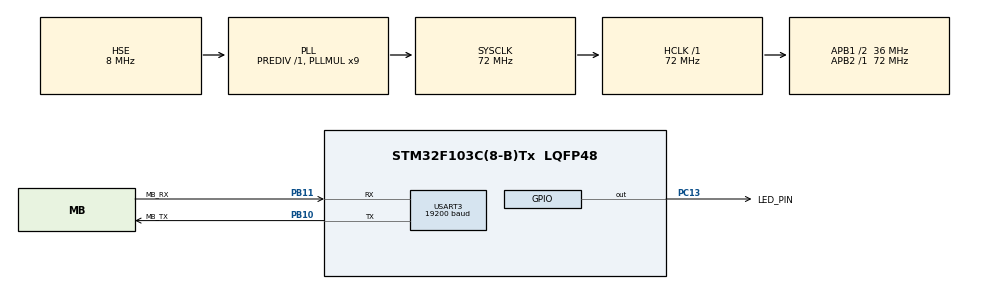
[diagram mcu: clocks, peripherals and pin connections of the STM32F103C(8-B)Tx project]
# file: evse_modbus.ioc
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Mcu.Family=STM32F1
Mcu.Name=STM32F103C(8-B)Tx
Mcu.Package=LQFP48
NVIC.PriorityGroup=NVIC_PRIORITYGROUP_4
NVIC.USART3_IRQn=true\:0\:0\:false\:false\:true\:true\:true\:true
PA13.Mode=Serial_Wire
PA13.Signal=SYS_JTMS-SWDIO
PA14.Mode=Serial_Wire
PA14.Signal=SYS_JTCK-SWCLK
PB10.GPIO_Label=MB_TX
PB10.Mode=Asynchronous
PB10.Signal=USART3_TX
PB11.GPIO_Label=MB_RX
PB11.Mode=Asynchronous
PB11.Signal=USART3_RX
PC13-TAMPER-RTC.GPIO_Label=LED_PIN
PC13-TAMPER-RTC.Signal=GPIO_Output
PD0-OSC_IN.Mode=HSE-External-Oscillator
PD0-OSC_IN.Signal=RCC_OSC_IN
PD1-OSC_OUT.Mode=HSE-External-Oscillator
PD1-OSC_OUT.Signal=RCC_OSC_OUT
ProjectManager.HeapSize=0x200
ProjectManager.StackSize=0x400
ProjectManager.TargetToolchain=MDK-ARM V5.32
RCC.AHBFreq_Value=72000000
RCC.APB1CLKDivider=RCC_HCLK_DIV2
RCC.APB1Freq_Value=36000000
RCC.APB1TimFreq_Value=72000000
RCC.APB2Freq_Value=72000000
RCC.APB2TimFreq_Value=72000000
RCC.HCLKFreq_Value=72000000
RCC.PLLMUL=RCC_PLL_MUL9
RCC.PLLSourceVirtual=RCC_PLLSOURCE_HSE
RCC.SYSCLKFreq_VALUE=72000000
RCC.SYSCLKSource=RCC_SYSCLKSOURCE_PLLCLK
RCC.USBFreq_Value=72000000
USART3.BaudRate=19200
USART3.VirtualMode=VM_ASYNC
board=custom

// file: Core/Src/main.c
/* USER CODE BEGIN Header */
/**
  ******************************************************************************
  * @file           : main.c
  * @brief          : Main program body
  ******************************************************************************
  * @attention
  *
  * Copyright (c) 2022 STMicroelectronics.
  * All rights reserved.
  *
  * This software is licensed under terms that can be found in the LICENSE file
  * in the root directory of this software component.
  * If no LICENSE file comes with this software, it is provided AS-IS.
  *
  ******************************************************************************
  */
/* USER CODE END Header */
#include "main.h"

/* USER CODE BEGIN Includes */
#include "stdbool.h"
#include "string.h"
#include "ModbusRTU.h"

/* USER CODE END Includes */

UART_HandleTypeDef huart3;

/* USER CODE BEGIN PV */
uint8_t rx_data;
static bool TimerIsEnabled = false;
static bool ByteIsReceived = false;

/* ----------------------- Static variables ---------------------------------*/
/* USER CODE END PV */

void SystemClock_Config(void);
static void MX_GPIO_Init(void);
static void MX_USART3_UART_Init(void);

/* USER CODE BEGIN 0 */
void Rx485TransmitterSwitch(bool on)
{
    if(on)
      HAL_GPIO_WritePin(LED_PIN_GPIO_Port, LED_PIN_Pin, GPIO_PIN_RESET);
    else
      HAL_GPIO_WritePin(LED_PIN_GPIO_Port, LED_PIN_Pin, GPIO_PIN_SET);
}

void SerialEnable( bool xRxEnable, bool xTxEnable )
{
  Rx485TransmitterSwitch(xTxEnable);

  if(xRxEnable)
  {
    HAL_UART_Receive_IT(&huart3, &rx_data, 1);
  }
  if(xTxEnable)
    prvvUARTTxReadyISR();

}

bool SerialInit( void )
{
  return true;
}

bool SerialPutByte( int8_t ucByte )
{
//  while(HAL_UART_Transmit_IT(&huart3, (uint8_t*)&ucByte, 1) == HAL_BUSY) {}
  if(HAL_UART_Transmit_IT(&huart3, (uint8_t*)&ucByte, 1) == HAL_BUSY)
  {
    return false;
  }

  return true;
}

bool SerialGetByte( int8_t * pucByte )
{
  bool res = (ByteIsReceived)?(true):(false);
  ByteIsReceived = false;
  *pucByte = rx_data;

  return res;
}

bool TimersInit( uint16_t usTim1Timerout50us )
{
    return true;
}

void TimersEnable( void )
{
    /* Enable the timer with the timeout passed to xMBPortTimersInit( ) */
    TimerIsEnabled = true;
}

void TimersDisable( void )
{
    /* Disable any pending timers. */
    TimerIsEnabled = false;
}

bool TimerExpired( void )
{
  prvvTIMERExpiredISR();
  return true;
}

bool InputsReadCb(uint16_t *p_data, uint16_t addr, uint16_t reg_count)
{
  while(reg_count-- > 0)
  {
    *p_data++ = reg_count+1;
  }

  return true;
}

bool CoilWrite(uint16_t addr, uint16_t value)
{
  return true;
}

bool HoldingReadCb(uint16_t *p_data, uint16_t addr, uint16_t reg_count)
{
  while(reg_count-- > 0)
  {
    *p_data++ = reg_count;
  }

  return true;
}

bool HoldingWrite(uint16_t addr, uint16_t value)
{
  return true;
}

void ModbusInit(void)
{
  init_modbus_struct_t mb_init;

  memset(&mb_init, 0, sizeof(init_modbus_struct_t));

  mb_init.mb_addr = 15;
// serial
  mb_init.serial.pSerialEnableCallback     = SerialEnable;
  mb_init.serial.pSerialInitCallback       = SerialInit;
  mb_init.serial.pSerialPutByteCallback    = SerialPutByte;
  mb_init.serial.pSerialGetByteCallback    = SerialGetByte;

// timer
  mb_init.timer.pTimersInitCallback    = TimersInit;
  mb_init.timer.pTimersEnableCallback  = TimersEnable;
  mb_init.timer.pTimersDisableCallback = TimersDisable;

// registers
  mb_init.regs_write_callbacks.inputsReadCb   = InputsReadCb;
  mb_init.regs_write_callbacks.holdingReadCb  = HoldingReadCb;
  mb_init.regs_write_callbacks.coilWriteCb    = CoilWrite;
  mb_init.regs_write_callbacks.holdingWriteCb = HoldingWrite;

  ModbusRtuInit(&mb_init);
}
// ----------------------------------------------------------------------------
void HAL_UART_TxCpltCallback(UART_HandleTypeDef *huart)
{
  if (huart->Instance == huart3.Instance)
  {
    __HAL_UART_CLEAR_OREFLAG(&huart3);
    prvvUARTTxReadyISR();
  }
}

void HAL_UART_RxCpltCallback(UART_HandleTypeDef *huart)
{
  if (huart->Instance == huart3.Instance)
  {
    __HAL_UART_CLEAR_OREFLAG(&huart3);
    ByteIsReceived = true;
    prvvUARTRxISR();
    HAL_UART_Receive_IT(&huart3, &rx_data, 1);
  }
}
/* USER CODE END 0 */

int main(void)
{

  /* MCU Configuration--------------------------------------------------------*/

  /* Reset of all peripherals, Initializes the Flash interface and the Systick. */
  HAL_Init();

  /* Configure the system clock */
  SystemClock_Config();

  /* Initialize all configured peripherals */
  MX_GPIO_Init();
  MX_USART3_UART_Init();
  /* USER CODE BEGIN 2 */

//  HAL_UART_Receive_IT(&huart3, rx_data, 1);

  /* USER CODE END 2 */

  /* Infinite loop */
  /* USER CODE BEGIN WHILE */
  uint32_t timer_ticks = 0;
  ModbusInit();

  while (1)
  {
    ModbusRun();

    if(!TimerIsEnabled)
      timer_ticks = HAL_GetTick();
    else if( (HAL_GetTick() - timer_ticks) > 10 )
    {
      timer_ticks = HAL_GetTick();
      TimerExpired();
//      HAL_GPIO_TogglePin(LED_PIN_GPIO_Port, LED_PIN_Pin);
    }
    /* USER CODE END WHILE */

  }
}

void SystemClock_Config(void)
{
  RCC_OscInitTypeDef RCC_OscInitStruct = {0};
  RCC_ClkInitTypeDef RCC_ClkInitStruct = {0};

  /** Initializes the RCC Oscillators according to the specified parameters
  * in the RCC_OscInitTypeDef structure.
  */
  RCC_OscInitStruct.OscillatorType = RCC_OSCILLATORTYPE_HSE;
  RCC_OscInitStruct.HSEState = RCC_HSE_ON;
  RCC_OscInitStruct.HSEPredivValue = RCC_HSE_PREDIV_DIV1;
  RCC_OscInitStruct.HSIState = RCC_HSI_ON;
  RCC_OscInitStruct.PLL.PLLState = RCC_PLL_ON;
  RCC_OscInitStruct.PLL.PLLSource = RCC_PLLSOURCE_HSE;
  RCC_OscInitStruct.PLL.PLLMUL = RCC_PLL_MUL9;
  if (HAL_RCC_OscConfig(&RCC_OscInitStruct) != HAL_OK)
  {
    Error_Handler();
  }

  /** Initializes the CPU, AHB and APB buses clocks
  */
  RCC_ClkInitStruct.ClockType = RCC_CLOCKTYPE_HCLK|RCC_CLOCKTYPE_SYSCLK
                              |RCC_CLOCKTYPE_PCLK1|RCC_CLOCKTYPE_PCLK2;
  RCC_ClkInitStruct.SYSCLKSource = RCC_SYSCLKSOURCE_PLLCLK;
  RCC_ClkInitStruct.AHBCLKDivider = RCC_SYSCLK_DIV1;
  RCC_ClkInitStruct.APB1CLKDivider = RCC_HCLK_DIV2;
  RCC_ClkInitStruct.APB2CLKDivider = RCC_HCLK_DIV1;

  if (HAL_RCC_ClockConfig(&RCC_ClkInitStruct, FLASH_LATENCY_2) != HAL_OK)
  {
    Error_Handler();
  }
}

static void MX_USART3_UART_Init(void)
{

  huart3.Instance = USART3;
  huart3.Init.BaudRate = 19200;
  huart3.Init.WordLength = UART_WORDLENGTH_8B;
  huart3.Init.StopBits = UART_STOPBITS_1;
  huart3.Init.Parity = UART_PARITY_NONE;
  huart3.Init.Mode = UART_MODE_TX_RX;
  huart3.Init.HwFlowCtl = UART_HWCONTROL_NONE;
  huart3.Init.OverSampling = UART_OVERSAMPLING_16;
  if (HAL_UART_Init(&huart3) != HAL_OK)
  {
    Error_Handler();
  }

}

static void MX_GPIO_Init(void)
{
  GPIO_InitTypeDef GPIO_InitStruct = {0};

  /* GPIO Ports Clock Enable */
  __HAL_RCC_GPIOC_CLK_ENABLE();
  __HAL_RCC_GPIOD_CLK_ENABLE();
  __HAL_RCC_GPIOB_CLK_ENABLE();
  __HAL_RCC_GPIOA_CLK_ENABLE();

  /*Configure GPIO pin Output Level */
  HAL_GPIO_WritePin(LED_PIN_GPIO_Port, LED_PIN_Pin, GPIO_PIN_RESET);

  /*Configure GPIO pin : LED_PIN_Pin */
  GPIO_InitStruct.Pin = LED_PIN_Pin;
  GPIO_InitStruct.Mode = GPIO_MODE_OUTPUT_PP;
  GPIO_InitStruct.Pull = GPIO_NOPULL;
  GPIO_InitStruct.Speed = GPIO_SPEED_FREQ_LOW;
  HAL_GPIO_Init(LED_PIN_GPIO_Port, &GPIO_InitStruct);

}

void Error_Handler(void)
{
  __disable_irq();
  while (1)
  {
  }
}
